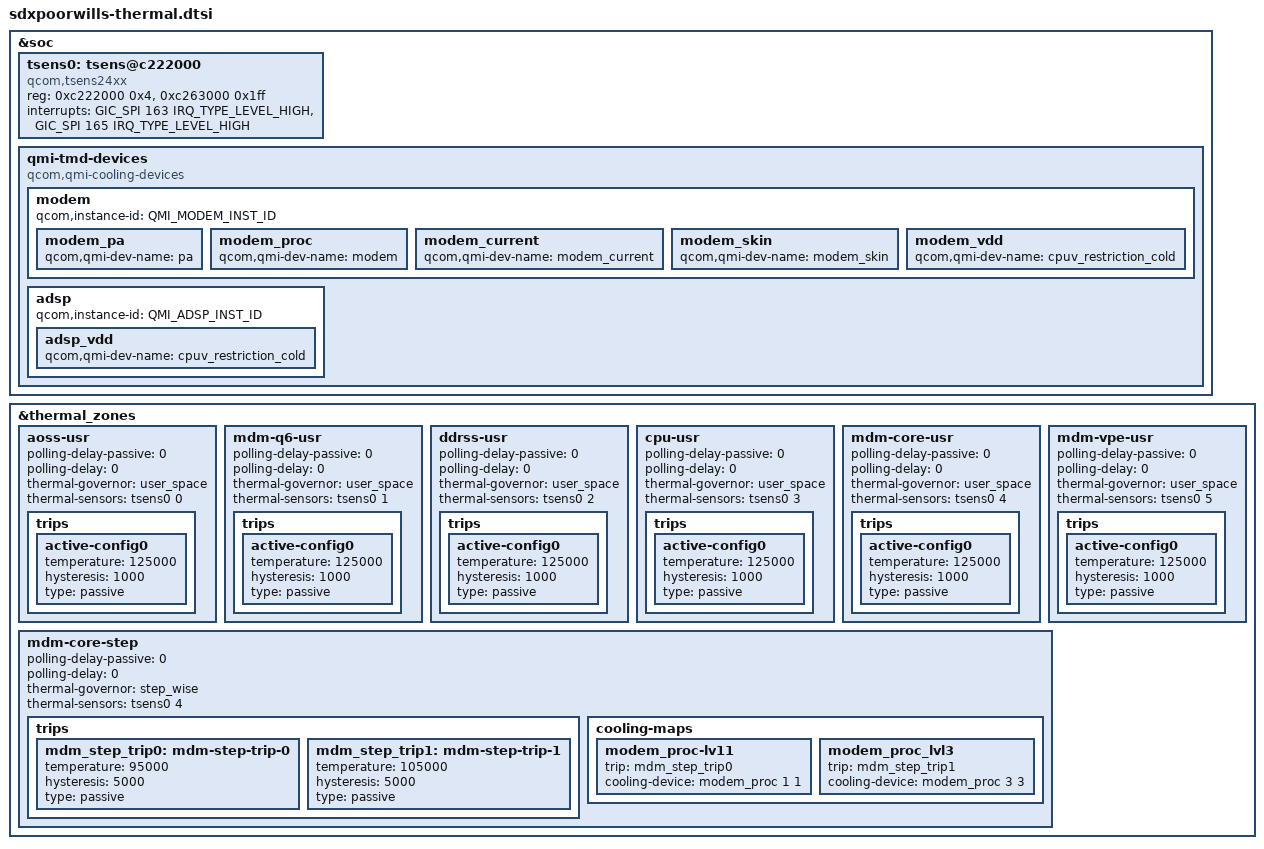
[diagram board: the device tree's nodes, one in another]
#include <dt-bindings/thermal/thermal.h>
#include <dt-bindings/thermal/thermal_qti.h>

&soc {
	tsens0: tsens@c222000 {
		compatible = "qcom,tsens24xx";
		reg = <0xc222000 0x4>,
		      <0xc263000 0x1ff>;
		reg-names = "tsens_srot_physical",
			    "tsens_tm_physical";
		interrupts = <GIC_SPI 163 IRQ_TYPE_LEVEL_HIGH>,
						<GIC_SPI 165 IRQ_TYPE_LEVEL_HIGH>;
		interrupt-names = "tsens-upper-lower", "tsens-critical";
		#thermal-sensor-cells = <1>;
	};

	qmi-tmd-devices {
		compatible = "qcom,qmi-cooling-devices";

		modem {
			qcom,instance-id = <QMI_MODEM_INST_ID>;

			modem_pa: modem_pa {
				qcom,qmi-dev-name = "pa";
				#cooling-cells = <2>;
			};

			modem_proc: modem_proc {
				qcom,qmi-dev-name = "modem";
				#cooling-cells = <2>;
			};

			modem_current: modem_current {
				qcom,qmi-dev-name = "modem_current";
				#cooling-cells = <2>;
			};

			modem_skin: modem_skin {
				qcom,qmi-dev-name = "modem_skin";
				#cooling-cells = <2>;
			};

			modem_vdd: modem_vdd {
				qcom,qmi-dev-name = "cpuv_restriction_cold";
				#cooling-cells = <2>;
			};
		};

		adsp {
			qcom,instance-id = <QMI_ADSP_INST_ID>;

			adsp_vdd: adsp_vdd {
				qcom,qmi-dev-name = "cpuv_restriction_cold";
				#cooling-cells = <2>;
			};
		};
	};
};

&thermal_zones {
	aoss-usr {
		polling-delay-passive = <0>;
		polling-delay = <0>;
		thermal-governor = "user_space";
		thermal-sensors = <&tsens0 0>;
		trips {
			active-config0 {
				temperature = <125000>;
				hysteresis = <1000>;
				type = "passive";
			};
		};
	};

	mdm-q6-usr {
		polling-delay-passive = <0>;
		polling-delay = <0>;
		thermal-governor = "user_space";
		thermal-sensors = <&tsens0 1>;
		trips {
			active-config0 {
				temperature = <125000>;
				hysteresis = <1000>;
				type = "passive";
			};
		};
	};

	ddrss-usr {
		polling-delay-passive = <0>;
		polling-delay = <0>;
		thermal-governor = "user_space";
		thermal-sensors = <&tsens0 2>;
		trips {
			active-config0 {
				temperature = <125000>;
				hysteresis = <1000>;
				type = "passive";
			};
		};
	};

	cpu-usr {
		polling-delay-passive = <0>;
		polling-delay = <0>;
		thermal-governor = "user_space";
		thermal-sensors = <&tsens0 3>;
		trips {
			active-config0 {
				temperature = <125000>;
				hysteresis = <1000>;
				type = "passive";
			};
		};
	};

	mdm-core-usr {
		polling-delay-passive = <0>;
		polling-delay = <0>;
		thermal-governor = "user_space";
		thermal-sensors = <&tsens0 4>;
		trips {
			active-config0 {
				temperature = <125000>;
				hysteresis = <1000>;
				type = "passive";
			};
		};
	};

	mdm-vpe-usr {
		polling-delay-passive = <0>;
		polling-delay = <0>;
		thermal-governor = "user_space";
		thermal-sensors = <&tsens0 5>;
		trips {
			active-config0 {
				temperature = <125000>;
				hysteresis = <1000>;
				type = "passive";
			};
		};
	};

	mdm-core-step {
		polling-delay-passive = <0>;
		polling-delay = <0>;
		thermal-governor = "step_wise";
		thermal-sensors = <&tsens0 4>;
		trips {
			mdm_step_trip0: mdm-step-trip-0 {
				temperature = <95000>;
				hysteresis = <5000>;
				type = "passive";
			};

			mdm_step_trip1: mdm-step-trip-1 {
				temperature = <105000>;
				hysteresis = <5000>;
				type = "passive";
			};
		};

		cooling-maps {
			modem_proc-lv11 {
				trip = <&mdm_step_trip0>;
				cooling-device = <&modem_proc 1 1>;
			};

			modem_proc_lvl3 {
				trip = <&mdm_step_trip1>;
				cooling-device = <&modem_proc 3 3>;
			};
		};
	};
};
